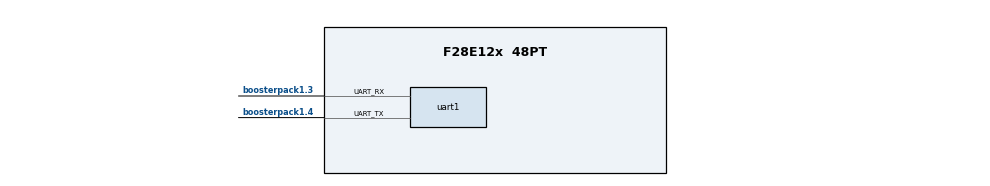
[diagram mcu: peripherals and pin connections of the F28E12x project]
/**
 * @cliArgs --board "/boards/LAUNCHXL_F28E12X" --device "F28E12x" --part "F28E12x_48PT" --package "48PT" --product "C2000WARE@6.00.00.00"
 * @versions {"tool":"1.23.999+220"}
 */

/**
 * Import the modules used in this configuration.
 */
const led       = scripting.addModule("/driverlib/board_components/led", {}, false);
const led1      = led.addInstance();
const cputimer  = scripting.addModule("/driverlib/cputimer.js", {}, false);
const cputimer1 = cputimer.addInstance();
const uart      = scripting.addModule("/driverlib/uart.js", {}, false);
const uart1     = uart.addInstance();

/**
 * Write custom configuration values to the imported modules.
 */
led1.$name     = "myBoardLED0";
led1.$hardware = system.deviceData.board.components.LED5;

cputimer1.$name                    = "myCPUTIMER0";
cputimer1.timerPrescaler           = 1;
cputimer1.timerPeriod              = 16000000;
cputimer1.enableInterrupt          = true;
cputimer1.registerInterrupts       = true;
cputimer1.timerInt.enableInterrupt = true;

uart1.$name                   = "myUART0";
uart1.baud                    = 9600;
uart1.registerInterrupts      = true;
uart1.enInterrupt             = false;
uart1.uart.uart_rxPin.$assign = "boosterpack1.3";
uart1.uart.uart_txPin.$assign = "boosterpack1.4";
uart1.rxQual.$name            = "myGPIOQUAL0";
uart1.txQual.$name            = "myGPIOQUAL1";
